# GD32F5HC register map
File version: 1.0
CPU: CM33 r0p4, little endian, MPU, FPU, 4 interrupt priority bits
Registers are 32-bit, read-write, reset 0x0 unless marked. A register's access mark holds for its fields unless they carry their own. Offsets are from the block's base; [hi:lo] are bit positions; {n}, {i} and the like mark numbered series; 'fields as' and 'values as' point back to an identical list.

## GPIOA — General-purpose I/Os
Base 0x40020000
Same registers: SEC_GPIOA 0x50020000
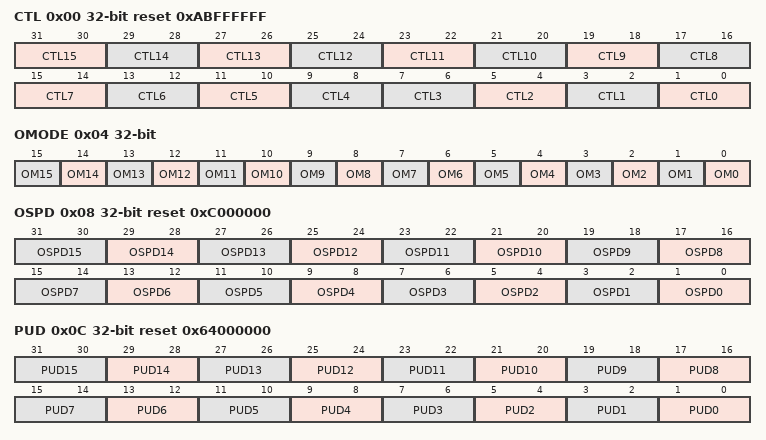
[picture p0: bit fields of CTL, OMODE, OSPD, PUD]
0x00 CTL reset 0xABFFFFFF — GPIO port control register
  [2n+1:2n] CTL{n} (n=7..15) — Port x configuration bits (x = {n})
  [13:12] CTL6 — Port x configuration bits (x = 6 )
  [11:10] CTL5 — Port x configuration bits (x = 5)
  [9:8] CTL4 — Port x configuration bits (x = 4 )
  [2n+1:2n] CTL{n} (n=0..3) — Port x configuration bits (x = {n})
0x04 OMODE — GPIO port output mode register
  [n] OM{n} (n=0..15) — Port {n} output mode bit
0x08 OSPD reset 0xC000000 — GPIO port output speed register
  [2n+1:2n] OSPD{n} (n=0..15) — Port {n} output max speed bits
0x0C PUD reset 0x64000000 — GPIO port pull-up/pull-down register
  [2n+1:2n] PUD{n} (n=0..15) — Port {n} pull-up or pull-down bits
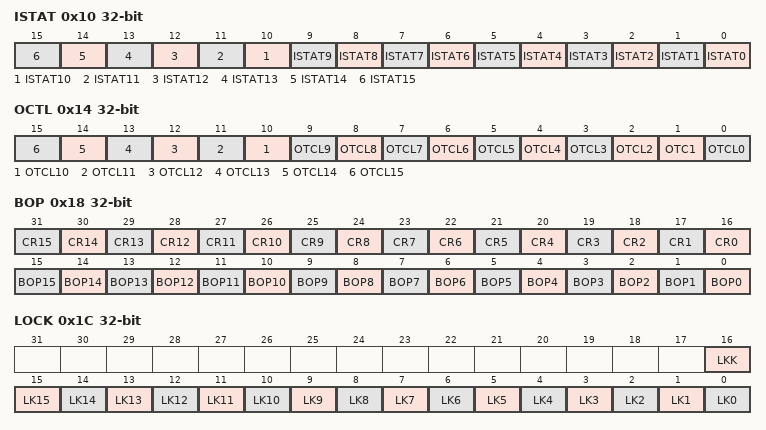
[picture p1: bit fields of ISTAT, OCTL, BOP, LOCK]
0x10 ISTAT ro — GPIO port input status register
  [n] ISTAT{n} (n=0..15) — Port input status (y = {n})
0x14 OCTL — Port output control register
  [n] OTCL{n} (n=2..15) — Pin output control(y=0..15)
  [1] OTC1 — Pin output control(y=0..15)
  [0] OTCL0 — Pin output control(y=0..15)
0x18 BOP wo — GPIO port bit operate register
  [n+16] CR{n} (n=0..15) — Port Clear bit {n}
  [n] BOP{n} (n=0..15) — Port Set bit {n}
0x1C LOCK — GPIO port configuration lock register
  [16] LKK — Lock sequence key
  [n] LK{n} (n=0..15) — Port Lock bit {n}
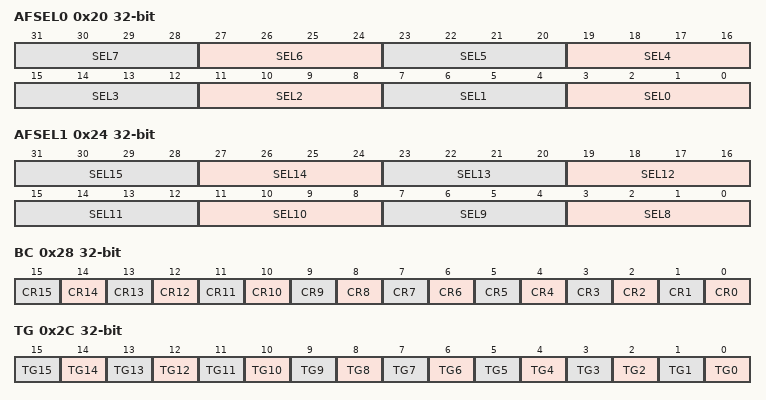
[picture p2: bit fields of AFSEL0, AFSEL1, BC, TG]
0x20 AFSEL0 — GPIO alternate function selected register 0
  [4n+3:4n] SEL{n} (n=0..7) — Port {n} alternate function selected
0x24 AFSEL1 — GPIO alternate function selected register 1
  [4n-29:4n-32] SEL{n} (n=8..15) — Port {n} alternate function selected
0x28 BC wo — Bit clear register
  [n] CR{n} (n=0..15) — Port cleat bit
0x2C TG wo — Port bit toggle register
  [n] TG{n} (n=0..15) — Port toggle bit
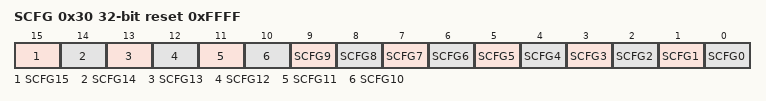
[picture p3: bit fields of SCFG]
0x30 SCFG reset 0xFFFF — GPIO secure configuration register
  [15] SCFG15 — Port A secure bit configure y (y= 15)
  [14] SCFG14 — Port A secure bit configure y (y= 14)
  [13] SCFG13 — Port A secure bit configure y (y= 13)
  [12] SCFG12 — Port A secure bit configure y (y= 12)
  [11] SCFG11 — Port A secure bit configure y (y= 11)
  [10] SCFG10 — Port A secure bit configure y (y= 10)
  [9] SCFG9 — Port A secure bit configure y (y= 9)
  [8] SCFG8 — Port A secure bit configure y (y= 8)
  [7] SCFG7 — Port A secure bit configure y (y= 7)
  [6] SCFG6 — Port A secure bit configure y (y= 6)
  [5] SCFG5 — Port A secure bit configure y (y= 5)
  [4] SCFG4 — Port A secure bit configure y (y= 4)
  [3] SCFG3 — Port A secure bit configure y (y= 3)
  [2] SCFG2 — Port A secure bit configure y (y= 2)
  [1] SCFG1 — Port A secure bit configure y (y= 1)
  [0] SCFG0 — Port A secure bit configure y (y= 0)

## GPIOB — General-purpose I/Os
Base 0x40020400
Same registers: SEC_GPIOB 0x50020400
Registers as GPIOA; these are added or differ:
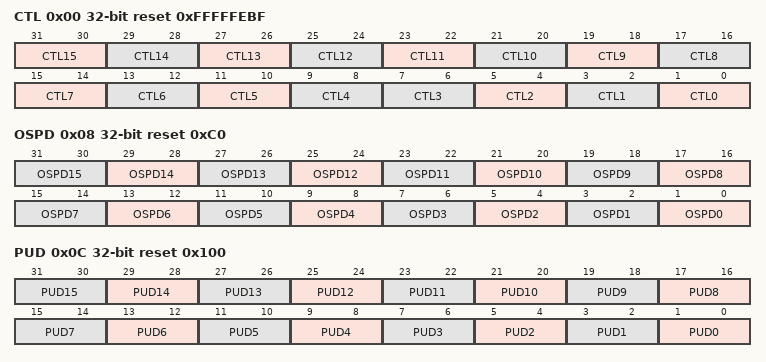
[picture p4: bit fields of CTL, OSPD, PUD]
0x00 CTL reset 0xFFFFFEBF — GPIO port control register
  fields as GPIOA.CTL
0x08 OSPD reset 0xC0 — GPIO port output speed register
  [2n+1:2n] OSPD{n} (n=0..15) — Port {n} output max speed bits
0x0C PUD reset 0x100 — GPIO port pull-up/pull-down register
  [2n+1:2n] PUD{n} (n=0..15) — Port {n} pull-up or pull-down bits

## GPIOC — General-purpose I/Os
Base 0x40020800
Same registers: SEC_GPIOC 0x50020800
Registers as GPIOA; these are added or differ:
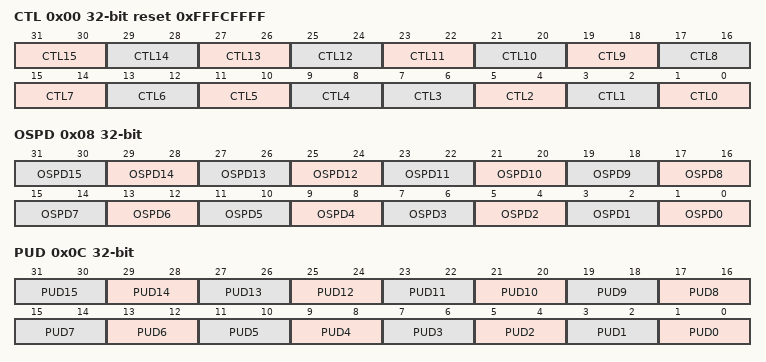
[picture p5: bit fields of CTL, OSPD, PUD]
0x00 CTL reset 0xFFFCFFFF — GPIO port control register
  fields as GPIOA.CTL
0x08 OSPD — GPIO port output speed register
  [2n+1:2n] OSPD{n} (n=0..15) — Port {n} output max speed bits
0x0C PUD — GPIO port pull-up/pull-down register
  [2n+1:2n] PUD{n} (n=0..15) — Port {n} pull-up or pull-down bits

## GPIOD — General-purpose I/Os
Base 0x40020C00
Same registers: SEC_GPIOD 0x50020C00
Registers as GPIOC; these are added or differ:
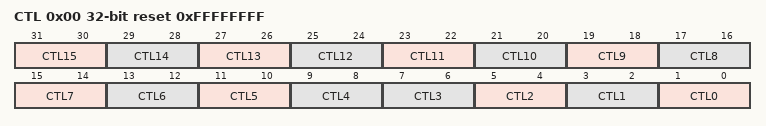
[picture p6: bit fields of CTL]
0x00 CTL reset 0xFFFFFFFF — GPIO port control register
  fields as GPIOA.CTL
